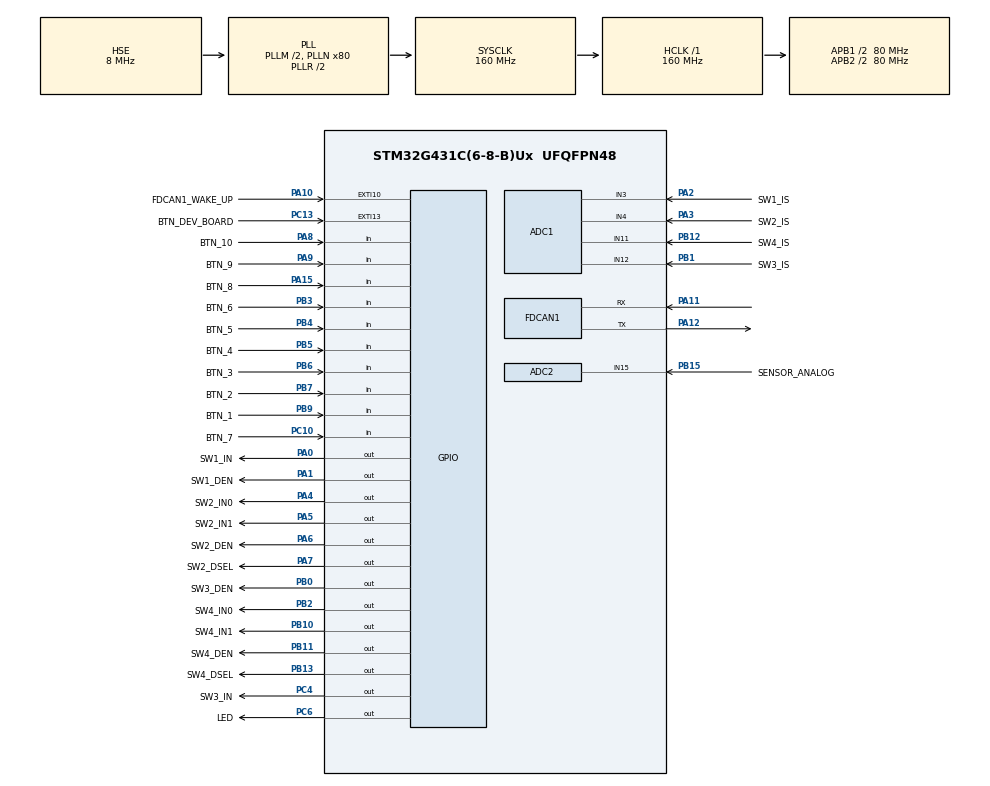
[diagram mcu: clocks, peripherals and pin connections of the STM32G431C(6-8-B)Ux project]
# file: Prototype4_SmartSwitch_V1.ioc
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ADC1.Channel-3\#ChannelRegularConversion=ADC_CHANNEL_3
ADC1.Channel-4\#ChannelRegularConversion=ADC_CHANNEL_4
ADC1.Channel-5\#ChannelRegularConversion=ADC_CHANNEL_11
ADC1.Channel-6\#ChannelRegularConversion=ADC_CHANNEL_12
ADC1.ClockPrescaler=ADC_CLOCK_ASYNC_DIV8
ADC1.ContinuousConvMode=DISABLE
ADC1.DMAContinuousRequests=DISABLE
ADC1.NbrOfConversion=4
ADC1.NbrOfConversionFlag=1
ADC1.OffsetNumber-3\#ChannelRegularConversion=ADC_OFFSET_NONE
ADC1.OffsetNumber-4\#ChannelRegularConversion=ADC_OFFSET_NONE
ADC1.OffsetNumber-5\#ChannelRegularConversion=ADC_OFFSET_NONE
ADC1.OffsetNumber-6\#ChannelRegularConversion=ADC_OFFSET_NONE
ADC1.Overrun=ADC_OVR_DATA_OVERWRITTEN
ADC1.Rank-3\#ChannelRegularConversion=1
ADC1.Rank-4\#ChannelRegularConversion=2
ADC1.Rank-5\#ChannelRegularConversion=3
ADC1.Rank-6\#ChannelRegularConversion=4
ADC1.SamplingTime-3\#ChannelRegularConversion=ADC_SAMPLETIME_247CYCLES_5
ADC1.SamplingTime-4\#ChannelRegularConversion=ADC_SAMPLETIME_247CYCLES_5
ADC1.SamplingTime-5\#ChannelRegularConversion=ADC_SAMPLETIME_247CYCLES_5
ADC1.SamplingTime-6\#ChannelRegularConversion=ADC_SAMPLETIME_247CYCLES_5
ADC1.master=1
ADC2.Channel-0\#ChannelRegularConversion=ADC_CHANNEL_15
ADC2.ClockPrescaler=ADC_CLOCK_ASYNC_DIV8
ADC2.ContinuousConvMode=ENABLE
ADC2.DMAContinuousRequests=ENABLE
ADC2.NbrOfConversion=1
ADC2.NbrOfConversionFlag=1
ADC2.OffsetNumber-0\#ChannelRegularConversion=ADC_OFFSET_NONE
ADC2.Overrun=ADC_OVR_DATA_OVERWRITTEN
ADC2.OversamplingMode=ENABLE
ADC2.Rank-0\#ChannelRegularConversion=1
ADC2.SamplingTime-0\#ChannelRegularConversion=ADC_SAMPLETIME_640CYCLES_5
Dma.ADC2.0.Direction=DMA_PERIPH_TO_MEMORY
Dma.ADC2.0.EventEnable=DISABLE
Dma.ADC2.0.Instance=DMA1_Channel2
Dma.ADC2.0.MemDataAlignment=DMA_MDATAALIGN_HALFWORD
Dma.ADC2.0.MemInc=DMA_MINC_ENABLE
Dma.ADC2.0.Mode=DMA_CIRCULAR
Dma.ADC2.0.PeriphDataAlignment=DMA_PDATAALIGN_HALFWORD
Dma.ADC2.0.PeriphInc=DMA_PINC_DISABLE
Dma.ADC2.0.Polarity=HAL_DMAMUX_REQ_GEN_RISING
Dma.ADC2.0.Priority=DMA_PRIORITY_LOW
Dma.ADC2.0.RequestNumber=1
Dma.ADC2.0.SignalID=NONE
Dma.ADC2.0.SyncEnable=DISABLE
Dma.ADC2.0.SyncPolarity=HAL_DMAMUX_SYNC_NO_EVENT
Dma.ADC2.0.SyncRequestNumber=1
Dma.ADC2.0.SyncSignalID=NONE
Dma.Request0=ADC2
FDCAN1.AutoRetransmission=ENABLE
FDCAN1.CalculateBaudRateNominal=1000000
FDCAN1.CalculateTimeBitNominal=1000
FDCAN1.CalculateTimeQuantumNominal=62.5
FDCAN1.DataPrescaler=2
FDCAN1.DataSyncJumpWidth=4
FDCAN1.DataTimeSeg1=15
FDCAN1.DataTimeSeg2=4
FDCAN1.FrameFormat=FDCAN_FRAME_FD_BRS
FDCAN1.Mode=FDCAN_MODE_NORMAL
FDCAN1.NominalPrescaler=5
FDCAN1.NominalSyncJumpWidth=3
FDCAN1.NominalTimeSeg1=12
FDCAN1.NominalTimeSeg2=3
Mcu.Family=STM32G4
Mcu.Name=STM32G431C(6-8-B)Ux
Mcu.Package=UFQFPN48
NVIC.ADC1_2_IRQn=true\:2\:0\:true\:false\:true\:true\:true\:true
NVIC.DMA1_Channel2_IRQn=true\:0\:0\:false\:false\:true\:false\:true\:true
NVIC.FDCAN1_IT0_IRQn=true\:0\:0\:false\:false\:true\:true\:true\:true
NVIC.FDCAN1_IT1_IRQn=true\:0\:0\:false\:false\:true\:true\:true\:true
NVIC.PriorityGroup=NVIC_PRIORITYGROUP_4
PA0.GPIO_Label=SW1_IN
PA0.Signal=GPIO_Output
PA1.GPIO_Label=SW1_DEN
PA1.Signal=GPIO_Output
PA10.GPIO_Label=FDCAN1_WAKE_UP
PA10.GPIO_ModeDefaultEXTI=GPIO_MODE_IT_FALLING
PA10.Signal=GPXTI10
PA11.GPIO_Speed=GPIO_SPEED_FREQ_VERY_HIGH
PA11.Mode=FDCAN_Activate
PA11.Signal=FDCAN1_RX
PA12.GPIO_Speed=GPIO_SPEED_FREQ_VERY_HIGH
PA12.Mode=FDCAN_Activate
PA12.Signal=FDCAN1_TX
PA13.Mode=Serial_Wire
PA13.Signal=SYS_JTMS-SWDIO
PA14.Mode=Serial_Wire
PA14.Signal=SYS_JTCK-SWCLK
PA15.GPIO_Label=BTN_8
PA15.GPIO_PuPd=GPIO_PULLUP
PA15.Signal=GPIO_Input
PA2.GPIO_Label=SW1_IS
PA2.Mode=IN3-Single-Ended
PA2.Signal=ADC1_IN3
PA3.GPIO_Label=SW2_IS
PA3.Mode=IN4-Single-Ended
PA3.Signal=ADC1_IN4
PA4.GPIO_Label=SW2_IN0
PA4.Signal=GPIO_Output
PA5.GPIO_Label=SW2_IN1
PA5.Signal=GPIO_Output
PA6.GPIO_Label=SW2_DEN
PA6.Signal=GPIO_Output
PA7.GPIO_Label=SW2_DSEL
PA7.Signal=GPIO_Output
PA8.GPIO_Label=BTN_10
PA8.GPIO_PuPd=GPIO_PULLUP
PA8.Signal=GPIO_Input
PA9.GPIO_Label=BTN_9
PA9.GPIO_PuPd=GPIO_PULLUP
PA9.Signal=GPIO_Input
PB0.GPIO_Label=SW3_DEN
PB0.Signal=GPIO_Output
PB1.GPIO_Label=SW3_IS
PB1.Mode=IN12-Single-Ended
PB1.Signal=ADC1_IN12
PB10.GPIO_Label=SW4_IN1
PB10.Signal=GPIO_Output
PB11.GPIO_Label=SW4_DEN
PB11.Signal=GPIO_Output
PB12.GPIO_Label=SW4_IS
PB12.Mode=IN11-Single-Ended
PB12.Signal=ADC1_IN11
PB13.GPIO_Label=SW4_DSEL
PB13.Signal=GPIO_Output
PB15.GPIO_Label=SENSOR_ANALOG
PB15.Mode=IN15-Single-Ended
PB15.Signal=ADC2_IN15
PB2.GPIO_Label=SW4_IN0
PB2.Signal=GPIO_Output
PB3.GPIO_Label=BTN_6
PB3.GPIO_PuPd=GPIO_PULLUP
PB3.Signal=GPIO_Input
PB4.GPIO_Label=BTN_5
PB4.GPIO_PuPd=GPIO_PULLUP
PB4.Signal=GPIO_Input
PB5.GPIO_Label=BTN_4
PB5.GPIO_PuPd=GPIO_PULLUP
PB5.Signal=GPIO_Input
PB6.GPIO_Label=BTN_3
PB6.GPIO_PuPd=GPIO_PULLUP
PB6.Signal=GPIO_Input
PB7.GPIO_Label=BTN_2
PB7.GPIO_PuPd=GPIO_PULLUP
PB7.Signal=GPIO_Input
PB9.GPIO_Label=BTN_1
PB9.GPIO_PuPd=GPIO_PULLUP
PB9.Signal=GPIO_Input
PC10.GPIO_Label=BTN_7
PC10.GPIO_PuPd=GPIO_PULLUP
PC10.Signal=GPIO_Input
PC13.GPIO_Label=BTN_DEV_BOARD
PC13.GPIO_ModeDefaultEXTI=GPIO_MODE_IT_RISING_FALLING
PC13.GPIO_PuPd=GPIO_PULLDOWN
PC13.Signal=GPXTI13
PC14-OSC32_IN.Mode=LSE-External-Oscillator
PC14-OSC32_IN.Signal=RCC_OSC32_IN
PC15-OSC32_OUT.Mode=LSE-External-Oscillator
PC15-OSC32_OUT.Signal=RCC_OSC32_OUT
PC4.GPIO_Label=SW3_IN
PC4.Signal=GPIO_Output
PC6.GPIO_Label=LED
PC6.Signal=GPIO_Output
PF0-OSC_IN.Mode=HSE-External-Oscillator
PF0-OSC_IN.Signal=RCC_OSC_IN
PF1-OSC_OUT.Mode=HSE-External-Oscillator
PF1-OSC_OUT.Signal=RCC_OSC_OUT
ProjectManager.HeapSize=0x200
ProjectManager.StackSize=0x400
ProjectManager.TargetToolchain=CMake
RCC.ADC12Freq_Value=160000000
RCC.AHBFreq_Value=160000000
RCC.APB1CLKDivider=RCC_HCLK_DIV2
RCC.APB1Freq_Value=80000000
RCC.APB1TimFreq_Value=160000000
RCC.APB2CLKDivider=RCC_HCLK_DIV2
RCC.APB2Freq_Value=80000000
RCC.APB2TimFreq_Value=160000000
RCC.CortexFreq_Value=160000000
RCC.EXTERNAL_CLOCK_VALUE=12288000
RCC.FDCANCLockSelection=RCC_FDCANCLKSOURCE_PLL
RCC.HCLKFreq_Value=160000000
RCC.HSE_VALUE=8000000
RCC.HSI48_VALUE=48000000
RCC.HSI_VALUE=16000000
RCC.PLLM=RCC_PLLM_DIV2
RCC.PLLN=80
RCC.PLLQ=RCC_PLLQ_DIV4
RCC.PLLSourceVirtual=RCC_PLLSOURCE_HSE
RCC.SYSCLKFreq_VALUE=160000000
RCC.SYSCLKSource=RCC_SYSCLKSOURCE_PLLCLK
RCC.USBFreq_Value=80000000
RCC.VCOOutputFreq_Value=320000000
VP_SYS_VS_DBSignals.Mode=DisableDeadBatterySignals
board=custom

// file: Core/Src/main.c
/* USER CODE BEGIN Header */
/**
  ******************************************************************************
  * @file           : main.c
  * @brief          : The main.c file.
  *                   This file contains the common defines of the application.
  ******************************************************************************
  * @attention
  *
  * Copyright (c) 2026 STMicroelectronics.
  * All rights reserved.
  *
  * This software is licensed under terms that can be found in the LICENSE file
  * in the root directory of this software component.
  * If no LICENSE file comes with this software, it is provided AS-IS.
  *
  ******************************************************************************
  */
/* USER CODE END Header */
#include "main.h"

/* USER CODE BEGIN Includes */

/*******************************************************************************
 *  CMC Include app logic header                                               *
 ******************************************************************************/

 #include "app/cmc_app_logic.h"

/* USER CODE END Includes */

ADC_HandleTypeDef hadc1;
ADC_HandleTypeDef hadc2;
DMA_HandleTypeDef hdma_adc2;

CRC_HandleTypeDef hcrc;

FDCAN_HandleTypeDef hfdcan1;

void SystemClock_Config(void);
static void MX_GPIO_Init(void);
static void MX_DMA_Init(void);
static void MX_FDCAN1_Init(void);
static void MX_ADC1_Init(void);
static void MX_ADC2_Init(void);
static void MX_CRC_Init(void);

int main(void)
{

  /* MCU Configuration--------------------------------------------------------*/

  /* Reset of all peripherals, Initializes the Flash interface and the Systick. */
  HAL_Init();

  /* Configure the system clock */
  SystemClock_Config();

  /* Initialize all configured peripherals */
  MX_GPIO_Init();
  MX_DMA_Init();
  MX_FDCAN1_Init();
  MX_ADC1_Init();
  MX_ADC2_Init();
  MX_CRC_Init();
  /* USER CODE BEGIN 2 */

  /*********************************************************************************
  *  CMC Main application logic init                                               *
  *********************************************************************************/

  cmc_app_init();

  /* USER CODE END 2 */

  /* Infinite loop */
  /* USER CODE BEGIN WHILE */
  while (1)
  {

  /**********************************************************************************
  *  CMC Start main application logic loop                                          *
  **********************************************************************************/

    cmc_app_process();

    /* USER CODE END WHILE */

  }
}

void SystemClock_Config(void)
{
  RCC_OscInitTypeDef RCC_OscInitStruct = {0};
  RCC_ClkInitTypeDef RCC_ClkInitStruct = {0};

  /** Configure the main internal regulator output voltage
  */
  HAL_PWREx_ControlVoltageScaling(PWR_REGULATOR_VOLTAGE_SCALE1_BOOST);

  /** Initializes the RCC Oscillators according to the specified parameters
  * in the RCC_OscInitTypeDef structure.
  */
  RCC_OscInitStruct.OscillatorType = RCC_OSCILLATORTYPE_HSE;
  RCC_OscInitStruct.HSEState = RCC_HSE_ON;
  RCC_OscInitStruct.PLL.PLLState = RCC_PLL_ON;
  RCC_OscInitStruct.PLL.PLLSource = RCC_PLLSOURCE_HSE;
  RCC_OscInitStruct.PLL.PLLM = RCC_PLLM_DIV2;
  RCC_OscInitStruct.PLL.PLLN = 80;
  RCC_OscInitStruct.PLL.PLLP = RCC_PLLP_DIV2;
  RCC_OscInitStruct.PLL.PLLQ = RCC_PLLQ_DIV4;
  RCC_OscInitStruct.PLL.PLLR = RCC_PLLR_DIV2;
  if (HAL_RCC_OscConfig(&RCC_OscInitStruct) != HAL_OK)
  {
    Error_Handler();
  }

  /** Initializes the CPU, AHB and APB buses clocks
  */
  RCC_ClkInitStruct.ClockType = RCC_CLOCKTYPE_HCLK|RCC_CLOCKTYPE_SYSCLK
                              |RCC_CLOCKTYPE_PCLK1|RCC_CLOCKTYPE_PCLK2;
  RCC_ClkInitStruct.SYSCLKSource = RCC_SYSCLKSOURCE_PLLCLK;
  RCC_ClkInitStruct.AHBCLKDivider = RCC_SYSCLK_DIV1;
  RCC_ClkInitStruct.APB1CLKDivider = RCC_HCLK_DIV2;
  RCC_ClkInitStruct.APB2CLKDivider = RCC_HCLK_DIV2;

  if (HAL_RCC_ClockConfig(&RCC_ClkInitStruct, FLASH_LATENCY_4) != HAL_OK)
  {
    Error_Handler();
  }
}

static void MX_ADC1_Init(void)
{

  ADC_MultiModeTypeDef multimode = {0};
  ADC_ChannelConfTypeDef sConfig = {0};

  /** Common config
  */
  hadc1.Instance = ADC1;
  hadc1.Init.ClockPrescaler = ADC_CLOCK_ASYNC_DIV8;
  hadc1.Init.Resolution = ADC_RESOLUTION_12B;
  hadc1.Init.DataAlign = ADC_DATAALIGN_RIGHT;
  hadc1.Init.GainCompensation = 0;
  hadc1.Init.ScanConvMode = ADC_SCAN_ENABLE;
  hadc1.Init.EOCSelection = ADC_EOC_SINGLE_CONV;
  hadc1.Init.LowPowerAutoWait = DISABLE;
  hadc1.Init.ContinuousConvMode = DISABLE;
  hadc1.Init.NbrOfConversion = 4;
  hadc1.Init.DiscontinuousConvMode = DISABLE;
  hadc1.Init.ExternalTrigConv = ADC_SOFTWARE_START;
  hadc1.Init.ExternalTrigConvEdge = ADC_EXTERNALTRIGCONVEDGE_NONE;
  hadc1.Init.DMAContinuousRequests = DISABLE;
  hadc1.Init.Overrun = ADC_OVR_DATA_OVERWRITTEN;
  hadc1.Init.OversamplingMode = DISABLE;
  if (HAL_ADC_Init(&hadc1) != HAL_OK)
  {
    Error_Handler();
  }

  /** Configure the ADC multi-mode
  */
  multimode.Mode = ADC_MODE_INDEPENDENT;
  if (HAL_ADCEx_MultiModeConfigChannel(&hadc1, &multimode) != HAL_OK)
  {
    Error_Handler();
  }

  /** Configure Regular Channel
  */
  sConfig.Channel = ADC_CHANNEL_3;
  sConfig.Rank = ADC_REGULAR_RANK_1;
  sConfig.SamplingTime = ADC_SAMPLETIME_247CYCLES_5;
  sConfig.SingleDiff = ADC_SINGLE_ENDED;
  sConfig.OffsetNumber = ADC_OFFSET_NONE;
  sConfig.Offset = 0;
  if (HAL_ADC_ConfigChannel(&hadc1, &sConfig) != HAL_OK)
  {
    Error_Handler();
  }

  /** Configure Regular Channel
  */
  sConfig.Channel = ADC_CHANNEL_4;
  sConfig.Rank = ADC_REGULAR_RANK_2;
  if (HAL_ADC_ConfigChannel(&hadc1, &sConfig) != HAL_OK)
  {
    Error_Handler();
  }

  /** Configure Regular Channel
  */
  sConfig.Channel = ADC_CHANNEL_11;
  sConfig.Rank = ADC_REGULAR_RANK_3;
  if (HAL_ADC_ConfigChannel(&hadc1, &sConfig) != HAL_OK)
  {
    Error_Handler();
  }

  /** Configure Regular Channel
  */
  sConfig.Channel = ADC_CHANNEL_12;
  sConfig.Rank = ADC_REGULAR_RANK_4;
  if (HAL_ADC_ConfigChannel(&hadc1, &sConfig) != HAL_OK)
  {
    Error_Handler();
  }

}

static void MX_ADC2_Init(void)
{

  ADC_ChannelConfTypeDef sConfig = {0};

  /** Common config
  */
  hadc2.Instance = ADC2;
  hadc2.Init.ClockPrescaler = ADC_CLOCK_ASYNC_DIV8;
  hadc2.Init.Resolution = ADC_RESOLUTION_12B;
  hadc2.Init.DataAlign = ADC_DATAALIGN_RIGHT;
  hadc2.Init.GainCompensation = 0;
  hadc2.Init.ScanConvMode = ADC_SCAN_DISABLE;
  hadc2.Init.EOCSelection = ADC_EOC_SINGLE_CONV;
  hadc2.Init.LowPowerAutoWait = DISABLE;
  hadc2.Init.ContinuousConvMode = ENABLE;
  hadc2.Init.NbrOfConversion = 1;
  hadc2.Init.DiscontinuousConvMode = DISABLE;
  hadc2.Init.ExternalTrigConv = ADC_SOFTWARE_START;
  hadc2.Init.ExternalTrigConvEdge = ADC_EXTERNALTRIGCONVEDGE_NONE;
  hadc2.Init.DMAContinuousRequests = ENABLE;
  hadc2.Init.Overrun = ADC_OVR_DATA_OVERWRITTEN;
  hadc2.Init.OversamplingMode = ENABLE;
  hadc2.Init.Oversampling.Ratio = ADC_OVERSAMPLING_RATIO_2;
  hadc2.Init.Oversampling.RightBitShift = ADC_RIGHTBITSHIFT_NONE;
  hadc2.Init.Oversampling.TriggeredMode = ADC_TRIGGEREDMODE_SINGLE_TRIGGER;
  hadc2.Init.Oversampling.OversamplingStopReset = ADC_REGOVERSAMPLING_CONTINUED_MODE;
  if (HAL_ADC_Init(&hadc2) != HAL_OK)
  {
    Error_Handler();
  }

  /** Configure Regular Channel
  */
  sConfig.Channel = ADC_CHANNEL_15;
  sConfig.Rank = ADC_REGULAR_RANK_1;
  sConfig.SamplingTime = ADC_SAMPLETIME_640CYCLES_5;
  sConfig.SingleDiff = ADC_SINGLE_ENDED;
  sConfig.OffsetNumber = ADC_OFFSET_NONE;
  sConfig.Offset = 0;
  if (HAL_ADC_ConfigChannel(&hadc2, &sConfig) != HAL_OK)
  {
    Error_Handler();
  }

}

static void MX_CRC_Init(void)
{

  hcrc.Instance = CRC;
  hcrc.Init.DefaultPolynomialUse = DEFAULT_POLYNOMIAL_ENABLE;
  hcrc.Init.DefaultInitValueUse = DEFAULT_INIT_VALUE_ENABLE;
  hcrc.Init.InputDataInversionMode = CRC_INPUTDATA_INVERSION_NONE;
  hcrc.Init.OutputDataInversionMode = CRC_OUTPUTDATA_INVERSION_DISABLE;
  hcrc.InputDataFormat = CRC_INPUTDATA_FORMAT_BYTES;
  if (HAL_CRC_Init(&hcrc) != HAL_OK)
  {
    Error_Handler();
  }

}

static void MX_FDCAN1_Init(void)
{

  hfdcan1.Instance = FDCAN1;
  hfdcan1.Init.ClockDivider = FDCAN_CLOCK_DIV1;
  hfdcan1.Init.FrameFormat = FDCAN_FRAME_FD_BRS;
  hfdcan1.Init.Mode = FDCAN_MODE_NORMAL;
  hfdcan1.Init.AutoRetransmission = ENABLE;
  hfdcan1.Init.TransmitPause = DISABLE;
  hfdcan1.Init.ProtocolException = DISABLE;
  hfdcan1.Init.NominalPrescaler = 5;
  hfdcan1.Init.NominalSyncJumpWidth = 3;
  hfdcan1.Init.NominalTimeSeg1 = 12;
  hfdcan1.Init.NominalTimeSeg2 = 3;
  hfdcan1.Init.DataPrescaler = 2;
  hfdcan1.Init.DataSyncJumpWidth = 4;
  hfdcan1.Init.DataTimeSeg1 = 15;
  hfdcan1.Init.DataTimeSeg2 = 4;
  hfdcan1.Init.StdFiltersNbr = 0;
  hfdcan1.Init.ExtFiltersNbr = 0;
  hfdcan1.Init.TxFifoQueueMode = FDCAN_TX_FIFO_OPERATION;
  if (HAL_FDCAN_Init(&hfdcan1) != HAL_OK)
  {
    Error_Handler();
  }

}

static void MX_DMA_Init(void)
{

  /* DMA controller clock enable */
  __HAL_RCC_DMAMUX1_CLK_ENABLE();
  __HAL_RCC_DMA1_CLK_ENABLE();

  /* DMA interrupt init */
  /* DMA1_Channel2_IRQn interrupt configuration */
  HAL_NVIC_SetPriority(DMA1_Channel2_IRQn, 0, 0);
  HAL_NVIC_EnableIRQ(DMA1_Channel2_IRQn);

}

static void MX_GPIO_Init(void)
{
  GPIO_InitTypeDef GPIO_InitStruct = {0};

  /* GPIO Ports Clock Enable */
  __HAL_RCC_GPIOC_CLK_ENABLE();
  __HAL_RCC_GPIOF_CLK_ENABLE();
  __HAL_RCC_GPIOA_CLK_ENABLE();
  __HAL_RCC_GPIOB_CLK_ENABLE();

  /*Configure GPIO pin Output Level */
  HAL_GPIO_WritePin(GPIOA, SW1_IN_Pin|SW1_DEN_Pin|SW2_IN0_Pin|SW2_IN1_Pin
                          |SW2_DEN_Pin|SW2_DSEL_Pin, GPIO_PIN_RESET);

  /*Configure GPIO pin Output Level */
  HAL_GPIO_WritePin(GPIOC, SW3_IN_Pin|LED_Pin, GPIO_PIN_RESET);

  /*Configure GPIO pin Output Level */
  HAL_GPIO_WritePin(GPIOB, SW3_DEN_Pin|SW4_IN0_Pin|SW4_IN1_Pin|SW4_DEN_Pin
                          |SW4_DSEL_Pin, GPIO_PIN_RESET);

  /*Configure GPIO pin : BTN_DEV_BOARD_Pin */
  GPIO_InitStruct.Pin = BTN_DEV_BOARD_Pin;
  GPIO_InitStruct.Mode = GPIO_MODE_IT_RISING_FALLING;
  GPIO_InitStruct.Pull = GPIO_PULLDOWN;
  HAL_GPIO_Init(BTN_DEV_BOARD_GPIO_Port, &GPIO_InitStruct);

  /*Configure GPIO pins : SW1_IN_Pin SW1_DEN_Pin SW2_IN0_Pin SW2_IN1_Pin
                           SW2_DEN_Pin SW2_DSEL_Pin */
  GPIO_InitStruct.Pin = SW1_IN_Pin|SW1_DEN_Pin|SW2_IN0_Pin|SW2_IN1_Pin
                          |SW2_DEN_Pin|SW2_DSEL_Pin;
  GPIO_InitStruct.Mode = GPIO_MODE_OUTPUT_PP;
  GPIO_InitStruct.Pull = GPIO_NOPULL;
  GPIO_InitStruct.Speed = GPIO_SPEED_FREQ_LOW;
  HAL_GPIO_Init(GPIOA, &GPIO_InitStruct);

  /*Configure GPIO pins : SW3_IN_Pin LED_Pin */
  GPIO_InitStruct.Pin = SW3_IN_Pin|LED_Pin;
  GPIO_InitStruct.Mode = GPIO_MODE_OUTPUT_PP;
  GPIO_InitStruct.Pull = GPIO_NOPULL;
  GPIO_InitStruct.Speed = GPIO_SPEED_FREQ_LOW;
  HAL_GPIO_Init(GPIOC, &GPIO_InitStruct);

  /*Configure GPIO pins : SW3_DEN_Pin SW4_IN0_Pin SW4_IN1_Pin SW4_DEN_Pin
                           SW4_DSEL_Pin */
  GPIO_InitStruct.Pin = SW3_DEN_Pin|SW4_IN0_Pin|SW4_IN1_Pin|SW4_DEN_Pin
                          |SW4_DSEL_Pin;
  GPIO_InitStruct.Mode = GPIO_MODE_OUTPUT_PP;
  GPIO_InitStruct.Pull = GPIO_NOPULL;
  GPIO_InitStruct.Speed = GPIO_SPEED_FREQ_LOW;
  HAL_GPIO_Init(GPIOB, &GPIO_InitStruct);

  /*Configure GPIO pins : BTN_10_Pin BTN_9_Pin BTN_8_Pin */
  GPIO_InitStruct.Pin = BTN_10_Pin|BTN_9_Pin|BTN_8_Pin;
  GPIO_InitStruct.Mode = GPIO_MODE_INPUT;
  GPIO_InitStruct.Pull = GPIO_PULLUP;
  HAL_GPIO_Init(GPIOA, &GPIO_InitStruct);

  /*Configure GPIO pin : FDCAN1_WAKE_UP_Pin */
  GPIO_InitStruct.Pin = FDCAN1_WAKE_UP_Pin;
  GPIO_InitStruct.Mode = GPIO_MODE_IT_FALLING;
  GPIO_InitStruct.Pull = GPIO_NOPULL;
  HAL_GPIO_Init(FDCAN1_WAKE_UP_GPIO_Port, &GPIO_InitStruct);

  /*Configure GPIO pin : BTN_7_Pin */
  GPIO_InitStruct.Pin = BTN_7_Pin;
  GPIO_InitStruct.Mode = GPIO_MODE_INPUT;
  GPIO_InitStruct.Pull = GPIO_PULLUP;
  HAL_GPIO_Init(BTN_7_GPIO_Port, &GPIO_InitStruct);

  /*Configure GPIO pins : BTN_6_Pin BTN_5_Pin BTN_4_Pin BTN_3_Pin
                           BTN_2_Pin BTN_1_Pin */
  GPIO_InitStruct.Pin = BTN_6_Pin|BTN_5_Pin|BTN_4_Pin|BTN_3_Pin
                          |BTN_2_Pin|BTN_1_Pin;
  GPIO_InitStruct.Mode = GPIO_MODE_INPUT;
  GPIO_InitStruct.Pull = GPIO_PULLUP;
  HAL_GPIO_Init(GPIOB, &GPIO_InitStruct);

}

void Error_Handler(void)
{
  __disable_irq();
  while (1)
  {
  }
}
